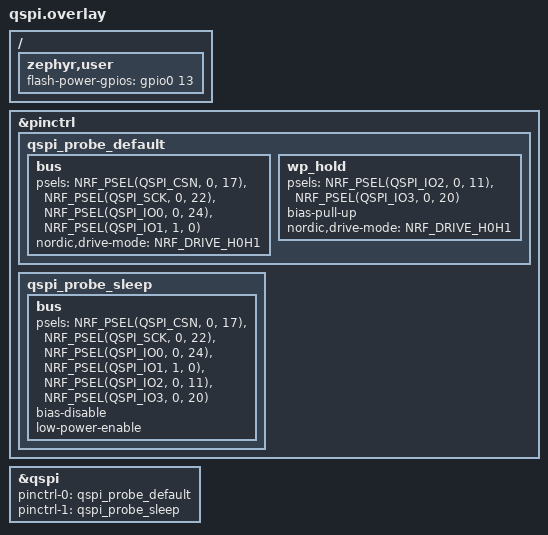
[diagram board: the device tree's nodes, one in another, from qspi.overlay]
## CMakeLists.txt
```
cmake_minimum_required(VERSION 3.20.0)
option(JAVELIN_PROBE "Run the native Javelin dictionary reader from external flash" OFF)
if(JAVELIN_PROBE)
  list(APPEND EXTRA_CONF_FILE "${CMAKE_CURRENT_SOURCE_DIR}/javelin.conf")
endif()
find_package(Zephyr REQUIRED HINTS $ENV{ZEPHYR_BASE})
project(steno_squid_qspi_probe)
target_sources(app PRIVATE src/main.c)

option(QUAD_PROBE "Build the separate quad-read diagnostic image" OFF)
option(SCRATCH_PROBE "Build the scratch-sector program and erase diagnostic image" OFF)
option(TRACE_PROBE "Repeat quad reads for waveform capture and timing comparison" OFF)
option(XIP_PROBE "Compare mapped quad reads with EasyDMA" OFF)
if(TRACE_PROBE AND NOT SCRATCH_PROBE)
  message(FATAL_ERROR "TRACE_PROBE requires SCRATCH_PROBE")
endif()
if(XIP_PROBE AND (NOT SCRATCH_PROBE OR TRACE_PROBE))
  message(FATAL_ERROR "XIP_PROBE requires SCRATCH_PROBE and a separate build from TRACE_PROBE")
endif()
if(JAVELIN_PROBE AND (NOT SCRATCH_PROBE OR XIP_PROBE OR TRACE_PROBE))
  message(FATAL_ERROR "JAVELIN_PROBE requires SCRATCH_PROBE and its own build directory")
endif()
if(QUAD_PROBE OR SCRATCH_PROBE)
  target_sources(app PRIVATE src/quad.c)
  target_compile_definitions(app PRIVATE QUAD_PROBE=1)
endif()
if(SCRATCH_PROBE)
  target_sources(app PRIVATE src/scratch.c)
  target_compile_definitions(app PRIVATE SCRATCH_PROBE=1)
endif()
if(TRACE_PROBE)
  target_sources(app PRIVATE src/trace.c)
  target_compile_definitions(app PRIVATE TRACE_PROBE=1)
endif()
if(XIP_PROBE OR JAVELIN_PROBE)
  target_sources(app PRIVATE src/mapped.c)
endif()
if(XIP_PROBE)
  target_compile_definitions(app PRIVATE XIP_PROBE=1)
endif()
if(JAVELIN_PROBE)
  include(javelin.cmake)
endif()
```

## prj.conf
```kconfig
CONFIG_GPIO=y
CONFIG_PINCTRL=y
CONFIG_NRFX_QSPI=y

CONFIG_BUILD_OUTPUT_UF2=y
CONFIG_BUILD_OUTPUT_UF2_FAMILY_ID="0xada52840"
CONFIG_USE_DT_CODE_PARTITION=y

CONFIG_USB_DEVICE_STACK=y
CONFIG_USB_DEVICE_INITIALIZE_AT_BOOT=n
CONFIG_USB_DEVICE_PRODUCT="Steno Squid QSPI Probe"
CONFIG_SERIAL=y
CONFIG_CONSOLE=y
CONFIG_UART_CONSOLE=y
CONFIG_UART_LINE_CTRL=y

CONFIG_LOG=y
CONFIG_LOG_MODE_IMMEDIATE=y
CONFIG_LOG_PRINTK=n
CONFIG_USE_SEGGER_RTT=y
CONFIG_LOG_BACKEND_RTT=y
CONFIG_LOG_BACKEND_UART=n
```

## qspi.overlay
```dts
#include <zephyr/dt-bindings/gpio/gpio.h>
#include <zephyr/dt-bindings/pinctrl/nrf-pinctrl.h>

/ {
	zephyr,user {
		flash-power-gpios = <&gpio0 13 GPIO_ACTIVE_HIGH>;
	};
};

&pinctrl {
	qspi_probe_default: qspi_probe_default {
		bus {
			psels = <NRF_PSEL(QSPI_CSN, 0, 17)>,
				<NRF_PSEL(QSPI_SCK, 0, 22)>,
				<NRF_PSEL(QSPI_IO0, 0, 24)>,
				<NRF_PSEL(QSPI_IO1, 1, 0)>;
			nordic,drive-mode = <NRF_DRIVE_H0H1>;
		};
		wp_hold {
			psels = <NRF_PSEL(QSPI_IO2, 0, 11)>,
				<NRF_PSEL(QSPI_IO3, 0, 20)>;
			bias-pull-up;
			nordic,drive-mode = <NRF_DRIVE_H0H1>;
		};
	};

	qspi_probe_sleep: qspi_probe_sleep {
		bus {
			psels = <NRF_PSEL(QSPI_CSN, 0, 17)>,
				<NRF_PSEL(QSPI_SCK, 0, 22)>,
				<NRF_PSEL(QSPI_IO0, 0, 24)>,
				<NRF_PSEL(QSPI_IO1, 1, 0)>,
				<NRF_PSEL(QSPI_IO2, 0, 11)>,
				<NRF_PSEL(QSPI_IO3, 0, 20)>;
			bias-disable;
			low-power-enable;
		};
	};
};

&qspi {
	status = "okay";
	pinctrl-0 = <&qspi_probe_default>;
	pinctrl-1 = <&qspi_probe_sleep>;
	pinctrl-names = "default", "sleep";
};
```

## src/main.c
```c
#include <nrfx_qspi.h>

#ifdef QUAD_PROBE
#include "quad.h"
#endif
#ifdef SCRATCH_PROBE
#include "scratch.h"
#endif

#include <zephyr/device.h>
#include <zephyr/devicetree.h>
#include <zephyr/drivers/gpio.h>
#include <zephyr/drivers/pinctrl.h>
#include <zephyr/drivers/uart.h>
#include <zephyr/kernel.h>
#include <zephyr/logging/log.h>
#include <zephyr/sys/printk.h>
#include <zephyr/usb/usb_device.h>

LOG_MODULE_REGISTER(qspi_probe);

#define QSPI_NODE DT_NODELABEL(qspi)

PINCTRL_DT_DEFINE(QSPI_NODE);

static const struct gpio_dt_spec flash_power =
	GPIO_DT_SPEC_GET(DT_PATH(zephyr_user), flash_power_gpios);
static const struct gpio_dt_spec status_led =
	GPIO_DT_SPEC_GET(DT_NODELABEL(blue_led), gpios);
static const struct device *const console = DEVICE_DT_GET(DT_CHOSEN(zephyr_console));

static const nrf_qspi_cinstr_conf_t read_id = {
	.opcode = 0x9f,
	.length = NRF_QSPI_CINSTR_LEN_4B,
	.io2_level = true,
	.io3_level = true,
	.wipwait = false,
	.wren = false,
};

struct probe_result {
	const char *failure;
	int gpio_or_pinctrl_error;
	nrfx_err_t nrfx_error;
	bool id_read;
	uint8_t id[3];
	uint8_t data[16] __aligned(4);
#ifdef QUAD_PROBE
	struct quad_result quad;
#endif
#ifdef SCRATCH_PROBE
	struct scratch_result scratch;
#endif
};

static void run_probe(struct probe_result *result)
{
	nrfx_qspi_config_t config = NRFX_QSPI_DEFAULT_CONFIG(
		NRF_QSPI_PIN_NOT_CONNECTED, NRF_QSPI_PIN_NOT_CONNECTED,
		NRF_QSPI_PIN_NOT_CONNECTED, NRF_QSPI_PIN_NOT_CONNECTED,
		NRF_QSPI_PIN_NOT_CONNECTED, NRF_QSPI_PIN_NOT_CONNECTED);

	/* Zephyr pinctrl supplies both the pin assignments and GPIO configuration. */
	config.skip_gpio_cfg = true;
	config.skip_psel_cfg = true;
	config.phy_if.sck_freq = NRF_QSPI_FREQ_DIV16;

	printk("Enabling switched flash VCC\n");
	if (!gpio_is_ready_dt(&flash_power)) {
		result->failure = "VCC GPIO device unavailable";
		return;
	}
	result->gpio_or_pinctrl_error = gpio_pin_configure_dt(&flash_power, GPIO_OUTPUT_ACTIVE);
	if (result->gpio_or_pinctrl_error) {
		result->failure = "VCC GPIO configuration";
		return;
	}
	k_msleep(50);

	printk("Applying QSPI pinctrl\n");
	result->gpio_or_pinctrl_error =
		pinctrl_apply_state(PINCTRL_DT_DEV_CONFIG_GET(QSPI_NODE), PINCTRL_STATE_DEFAULT);
	if (result->gpio_or_pinctrl_error) {
		result->failure = "QSPI pinctrl";
		return;
	}

	printk("Initializing Nordic QSPI (2 MHz, FASTREAD, 24-bit address)\n");
	result->nrfx_error = nrfx_qspi_init(&config, NULL, NULL);
	if (result->nrfx_error != NRFX_SUCCESS) {
		result->failure = "nrfx_qspi_init";
		return;
	}

	printk("Activating QSPI\n");
	result->nrfx_error = nrfx_qspi_activate(true);
	if (result->nrfx_error != NRFX_SUCCESS) {
		result->failure = "nrfx_qspi_activate";
		return;
	}

	printk("Reading JEDEC ID (0x9F)\n");
	result->nrfx_error = nrfx_qspi_cinstr_xfer(&read_id, NULL, result->id);
	if (result->nrfx_error != NRFX_SUCCESS) {
		result->failure = "JEDEC ID transfer";
		return;
	}
	result->id_read = true;

	if (result->id[0] != 0xef || result->id[1] != 0x40 || result->id[2] != 0x18) {
		result->failure = "unexpected JEDEC ID";
		return;
	}

	printk("Reading 16 bytes at 0x000000 with FASTREAD (0x0B)\n");
	result->nrfx_error = nrfx_qspi_read(result->data, sizeof(result->data), 0);
	if (result->nrfx_error != NRFX_SUCCESS) {
		result->failure = "FASTREAD transfer";
		return;
	}
#ifdef SCRATCH_PROBE
	run_scratch_probe(&config, &result->scratch, &result->quad);
#elif defined(QUAD_PROBE)
	run_quad_probe(&config, &result->quad, 0, 64 * 1024);
#endif
}

static void print_result(const struct probe_result *result)
{
	if (result->id_read) {
		printk("JEDEC ID: %02X %02X %02X (expected EF 40 18)\n",
		       result->id[0], result->id[1], result->id[2]);
	}
	if (result->failure) {
		printk("FAIL: %s; Zephyr rc=%d, nrfx rc=0x%08x\n",
		       result->failure, result->gpio_or_pinctrl_error, (unsigned int)result->nrfx_error);
		return;
	}

	printk("FASTREAD 0x000000:");
	for (size_t i = 0; i < sizeof(result->data); i++) {
		printk(" %02X", result->data[i]);
	}
#ifdef SCRATCH_PROBE
	printk("\nScratch %s (nrfx rc=0x%08x)\n",
	       result->scratch.outcome, (unsigned int)result->scratch.error);
	if (result->scratch.cleanup) {
		printk("Scratch cleanup %s (nrfx rc=0x%08x)\n",
		       result->scratch.cleanup, (unsigned int)result->scratch.cleanup_error);
	}
#endif
#ifdef QUAD_PROBE
	if (result->quad.outcome) {
		printk("\nQuad %s (compared %u bytes, lane mask 0x%x, nrfx rc=0x%08x)\n",
		       result->quad.outcome, result->quad.compared_bytes, result->quad.lane_coverage,
		       (unsigned int)result->quad.error);
#ifdef XIP_PROBE
		if (result->quad.mapped.outcome) {
			printk("XIP %s (matched %u words, nrfx rc=0x%08x)\n",
			       result->quad.mapped.outcome, result->quad.mapped.matched_words,
			       (unsigned int)result->quad.mapped.dma_error);
		}
#endif
#ifdef JAVELIN_PROBE
		if (result->quad.javelin_outcome) {
			printk("Javelin %s\n", result->quad.javelin_outcome);
			if (result->quad.phrase[0]) {
				printk("Javelin phrase: %s\n", result->quad.phrase);
			}
		}
#endif
		if (result->quad.restore_error != NRFX_SUCCESS) {
			printk("Quad SR2 restore failed: nrfx rc=0x%08x; power-cycle the flash\n",
			       (unsigned int)result->quad.restore_error);
		}
	}
#else
	printk("\nPASS: JEDEC ID and 16-byte single-data-line read completed\n");
#endif
}

int main(void)
{
	struct probe_result result = {.nrfx_error = NRFX_SUCCESS};
	uint32_t dtr = 0;
	bool led_ready = gpio_is_ready_dt(&status_led) &&
			 gpio_pin_configure_dt(&status_led, GPIO_OUTPUT_ACTIVE) == 0;
	int rc = device_is_ready(console) ? usb_enable(NULL) : -ENODEV;

	if (rc) {
		LOG_ERR("USB CDC startup failed: %d", rc);
		for (;;) {
			if (led_ready) {
				gpio_pin_toggle_dt(&status_led);
			}
			k_msleep(120);
		}
	}

	while (!dtr) {
		rc = uart_line_ctrl_get(console, UART_LINE_CTRL_DTR, &dtr);
		if (rc) {
			LOG_ERR("CDC DTR query failed: %d", rc);
		}
		k_msleep(100);
	}
	if (led_ready) {
		gpio_pin_set_dt(&status_led, 0);
	}

#ifdef TRACE_PROBE
	printk("\nSteno Squid QSPI trace ready. Arm the analyzer, then send t.\n");
	for (;;) {
		unsigned char key;

		if (uart_poll_in(console, &key) == 0 && key == 't') {
			break;
		}
		k_msleep(20);
	}
#elif defined(XIP_PROBE)
	printk("\nSteno Squid QSPI probe - mapped quad data reads\n");
#elif defined(JAVELIN_PROBE)
	printk("\nSteno Squid QSPI probe - native Javelin mapped dictionary\n");
#elif defined(SCRATCH_PROBE)
	printk("\nSteno Squid QSPI probe - scratch-sector program, read and erase\n");
#elif defined(QUAD_PROBE)
	printk("\n%s - quad output with volatile QE if needed\n", CONFIG_USB_DEVICE_PRODUCT);
#else
	printk("\n%s - read only\n", CONFIG_USB_DEVICE_PRODUCT);
#endif
	run_probe(&result);
	for (;;) {
		print_result(&result);
		k_sleep(K_SECONDS(3));
	}
}
```

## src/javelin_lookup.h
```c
#ifndef STENO_SQUID_JAVELIN_LOOKUP_H
#define STENO_SQUID_JAVELIN_LOOKUP_H

#include <stdint.h>

#ifdef __cplusplus
extern "C" {
#endif

extern const uint8_t javelin_fixture_start[];
extern const uint8_t javelin_fixture_end[];

const char *javelin_lookup_phrase(uintptr_t address, char *phrase);
#define JAVELIN_PHRASE_SIZE 32

#ifdef __cplusplus
}
#endif

#endif
```

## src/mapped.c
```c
#include "mapped.h"
#include "scratch.h"

#include <zephyr/devicetree.h>
#include <zephyr/kernel.h>
#include <zephyr/sys/printk.h>

#define XIP_BASE DT_REG_ADDR_BY_NAME(DT_NODELABEL(qspi), qspi_mm)
#define PAGE_WORDS (QUAD_SAMPLE_SIZE / sizeof(uint32_t))

static uint32_t dma_page[2][PAGE_WORDS];

void run_mapped_probe(struct mapped_result *result, uint32_t first_address)
{
	const uint32_t addresses[] = {first_address, result->second_address};
	const uint8_t patterns[] = {SCRATCH_FIRST_PATTERN, SCRATCH_SECOND_PATTERN};
	uintptr_t mismatch_address = 0;
	uint32_t mismatch_expected = 0;
	uint32_t mismatch_actual = 0;

	for (size_t page = 0; page < ARRAY_SIZE(addresses); page++) {
		result->dma_error = nrfx_qspi_read(dma_page[page], sizeof(dma_page[page]),
						 addresses[page]);
		if (result->dma_error != NRFX_SUCCESS) {
			result->outcome = "FAIL: quad EasyDMA reference read";
			return;
		}
		const uint8_t *reference = (const uint8_t *)dma_page[page];

		for (size_t byte = 0; byte < sizeof(dma_page[page]); byte++) {
			if (reference[byte] != ((uint8_t)byte ^ patterns[page])) {
				printk("Quad EasyDMA pattern mismatch at 0x%06x\n",
				       addresses[page] + (unsigned int)byte);
				result->outcome = "FAIL: quad EasyDMA reference differs from programmed pattern";
				return;
			}
		}
	}

	printk("Reading mapped quad pages at 0x%08x and 0x%08x\n",
	       (unsigned int)(XIP_BASE + addresses[0]), (unsigned int)(XIP_BASE + addresses[1]));
	for (size_t page = 0; page < ARRAY_SIZE(addresses); page++) {
		const volatile uint32_t *mapped =
			(const volatile uint32_t *)(XIP_BASE + addresses[page]);

		for (size_t word = 0; word < PAGE_WORDS; word++) {
			uint32_t actual = mapped[word];
			uint32_t expected = dma_page[page][word];

			if (actual == expected) {
				result->matched_words++;
			} else if (mismatch_address == 0) {
				mismatch_address = (uintptr_t)&mapped[word];
				mismatch_expected = expected;
				mismatch_actual = actual;
			}
		}
	}

	if (!reactivate_after_xip()) {
		result->reactivation_failed = true;
		result->outcome = "FAIL: QSPI did not become ready after mapped reads";
		return;
	}
	if (mismatch_address) {
		printk("Mapped mismatch at 0x%08x: expected %08x, got %08x\n",
		       (unsigned int)mismatch_address, mismatch_expected, mismatch_actual);
		result->outcome = "FAIL: mapped reads differ from quad EasyDMA";
		return;
	}
	result->outcome = "PASS: both mapped pages match quad EasyDMA";
}
```

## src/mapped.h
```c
#ifndef STENO_SQUID_MAPPED_H
#define STENO_SQUID_MAPPED_H

#include <nrfx_qspi.h>

struct mapped_result {
	const char *outcome;
	uint32_t second_address;
	unsigned int matched_words;
	nrfx_err_t dma_error;
	bool reactivation_failed;
};

void run_mapped_probe(struct mapped_result *result, uint32_t first_address);

#endif
```

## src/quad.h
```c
#ifndef STENO_SQUID_QUAD_H
#define STENO_SQUID_QUAD_H

#include <nrfx_qspi.h>
#ifdef XIP_PROBE
#include "mapped.h"
#endif
#ifdef JAVELIN_PROBE
#include "javelin_lookup.h"
#endif

struct quad_result {
	const char *outcome;
	nrfx_err_t error;
	nrfx_err_t restore_error;
	uint32_t compared_bytes;
	uint8_t lane_coverage;
#ifdef XIP_PROBE
	struct mapped_result mapped;
#endif
#ifdef JAVELIN_PROBE
	const char *javelin_outcome;
	char phrase[JAVELIN_PHRASE_SIZE];
	bool javelin_reactivation_failed;
#endif
};

#define QUAD_SAMPLE_SIZE 256

nrfx_err_t w25q128_enable_volatile_quad(void);
bool reactivate_after_xip(void);

void run_quad_probe(nrfx_qspi_config_t *config, struct quad_result *result,
		    uint32_t start, uint32_t length);

#endif
```

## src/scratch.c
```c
#include "scratch.h"

#include <string.h>
#include <zephyr/kernel.h>
#include <zephyr/sys/printk.h>

#define FLASH_BYTES (16U * 1024U * 1024U)
#define SECTOR_BYTES 4096U
#define SCRATCH_ADDRESS (FLASH_BYTES - SECTOR_BYTES)
#define PAGE_BYTES QUAD_SAMPLE_SIZE

static uint8_t page[PAGE_BYTES] __aligned(4);
static uint8_t readback[PAGE_BYTES] __aligned(4);

static nrfx_err_t wait_until_ready(void)
{
	int64_t deadline = k_uptime_get() + 2000;

	do {
		nrfx_err_t rc = nrfx_qspi_mem_busy_check();

		if (rc != NRFX_ERROR_BUSY) {
			return rc;
		}
		k_msleep(2);
	} while (k_uptime_get() < deadline);

	return NRFX_ERROR_TIMEOUT;
}

static nrfx_err_t verify_erased(bool *blank)
{
	*blank = false;
	for (uint32_t offset = 0; offset < SECTOR_BYTES; offset += sizeof(readback)) {
		nrfx_err_t rc = nrfx_qspi_read(readback, sizeof(readback), SCRATCH_ADDRESS + offset);

		if (rc != NRFX_SUCCESS) {
			return rc;
		}
		for (size_t i = 0; i < sizeof(readback); i++) {
			if (readback[i] != 0xff) {
				return NRFX_SUCCESS;
			}
		}
	}
	*blank = true;
	return NRFX_SUCCESS;
}

#ifndef JAVELIN_PROBE
static void fill_pattern(uint8_t pattern)
{
	for (size_t i = 0; i < sizeof(page); i++) {
		page[i] = (uint8_t)i ^ pattern;
	}
}
#endif

static const char *program_and_read(uint32_t address, nrfx_err_t *rc)
{
	printk("Programming %u bytes at 0x%06x (single-data-line Page Program)\n",
	       (unsigned int)sizeof(page), address);
	*rc = nrfx_qspi_write(page, sizeof(page), address);
	if (*rc != NRFX_SUCCESS) {
		return "FAIL: page program command";
	}
	*rc = wait_until_ready();
	if (*rc != NRFX_SUCCESS) {
		return "FAIL: waiting for page program";
	}
	*rc = nrfx_qspi_read(readback, sizeof(readback), address);
	if (*rc != NRFX_SUCCESS) {
		return "FAIL: programmed page read";
	}
	if (memcmp(page, readback, sizeof(page)) != 0) {
		for (size_t i = 0; i < sizeof(page); i++) {
			if (page[i] != readback[i]) {
				printk("Mismatch at 0x%06x: expected %02X, got %02X\n",
				       address + (unsigned int)i, page[i], readback[i]);
				break;
			}
		}
		return "FAIL: programmed page differs from expected pattern";
	}
	return NULL;
}

static const char *erase_and_verify(nrfx_qspi_config_t *config, nrfx_err_t *rc)
{
	bool blank;

	config->prot_if.readoc = NRF_QSPI_READOC_FASTREAD;
	*rc = nrfx_qspi_reconfigure(config);
	if (*rc != NRFX_SUCCESS) {
		return "FAIL: reconfiguring single-data-line reads";
	}
	*rc = wait_until_ready();
	if (*rc != NRFX_SUCCESS) {
		return "FAIL: waiting before sector erase";
	}
	printk("Erasing the 4 KiB scratch sector at 0x%06x\n", SCRATCH_ADDRESS);
	*rc = nrfx_qspi_erase(NRF_QSPI_ERASE_LEN_4KB, SCRATCH_ADDRESS);
	if (*rc != NRFX_SUCCESS) {
		return "FAIL: sector erase command";
	}
	*rc = wait_until_ready();
	if (*rc != NRFX_SUCCESS) {
		return "FAIL: waiting for sector erase";
	}
	*rc = verify_erased(&blank);
	if (*rc != NRFX_SUCCESS) {
		return "FAIL: reading sector after erase";
	}
	return blank ? "PASS: all 4,096 bytes verified as FF" : "FAIL: sector still contains data";
}

void run_scratch_probe(nrfx_qspi_config_t *config, struct scratch_result *result,
		       struct quad_result *quad)
{
	bool blank;

	printk("Checking all 4 KiB at 0x%06x before writing\n", SCRATCH_ADDRESS);
	result->error = verify_erased(&blank);
	if (result->error != NRFX_SUCCESS) {
		result->outcome = "FAIL: initial scratch-sector read";
		return;
	}
	if (!blank) {
		result->outcome = "SKIP: scratch sector contains data";
		return;
	}

#ifdef JAVELIN_PROBE
	const size_t fixture_size = javelin_fixture_end - javelin_fixture_start;
	if (fixture_size == 0 || fixture_size > sizeof(page)) {
		result->outcome = "FAIL: Javelin fixture does not fit scratch page";
		return;
	}
	memset(page, 0xff, sizeof(page));
	memcpy(page, javelin_fixture_start, fixture_size);
	printk("Staging %u-byte JSC4 fixture in the external scratch sector\n",
	       (unsigned int)fixture_size);
#else
	fill_pattern(SCRATCH_FIRST_PATTERN);
#endif
	result->outcome = program_and_read(SCRATCH_ADDRESS, &result->error);
#ifdef XIP_PROBE
	quad->mapped.second_address = SCRATCH_ADDRESS + SECTOR_BYTES - PAGE_BYTES;
	if (!result->outcome) {
		fill_pattern(SCRATCH_SECOND_PATTERN);
		result->outcome = program_and_read(quad->mapped.second_address, &result->error);
	}
#endif
	if (!result->outcome) {
#ifdef XIP_PROBE
		result->outcome = "PASS: both 256-byte programmed pages matched";
#else
		result->outcome = "PASS: all 256 programmed bytes matched";
#endif
		run_quad_probe(config, quad, SCRATCH_ADDRESS, sizeof(page));
	}
#ifdef XIP_PROBE
	if (quad->mapped.reactivation_failed) {
#elif defined(JAVELIN_PROBE)
	if (quad->javelin_reactivation_failed) {
#endif
#if defined(XIP_PROBE) || defined(JAVELIN_PROBE)
		result->cleanup = "SKIP: QSPI reactivation failed; scratch data may remain";
		result->cleanup_error = NRFX_ERROR_TIMEOUT;
		return;
	}
#endif
	result->cleanup = erase_and_verify(config, &result->cleanup_error);
}
```

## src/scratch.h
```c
#ifndef STENO_SQUID_SCRATCH_H
#define STENO_SQUID_SCRATCH_H

#include "quad.h"

#define SCRATCH_FIRST_PATTERN 0xa5
#define SCRATCH_SECOND_PATTERN 0x3c

struct scratch_result {
	const char *outcome;
	const char *cleanup;
	nrfx_err_t error;
	nrfx_err_t cleanup_error;
};

void run_scratch_probe(nrfx_qspi_config_t *config, struct scratch_result *result,
		       struct quad_result *quad);

#endif
```

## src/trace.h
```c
#ifndef STENO_SQUID_TRACE_H
#define STENO_SQUID_TRACE_H

#include <stdint.h>

void run_quad_trace(uint32_t address, const uint8_t *expected);

#endif
```

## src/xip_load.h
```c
#ifndef STENO_SQUID_XIP_LOAD_H
#define STENO_SQUID_XIP_LOAD_H

#include <stddef.h>
#include <stdint.h>

// Keep subword reads out of the memory window (erratum 118), and serialize
// each load before using its value in a dependent access (erratum 216).
static inline uint32_t xip_load_word(const void *address)
{
	const auto value = *static_cast<const volatile uint32_t *>(address);
	asm volatile("dsb" ::: "memory");
	return value;
}

static inline uint8_t xip_load_byte(const void *address)
{
	const auto offset = reinterpret_cast<uintptr_t>(address);
	const auto word = xip_load_word(reinterpret_cast<const void *>(offset & ~uintptr_t(3)));
	return static_cast<uint8_t>(word >> (8 * (offset & 3)));
}

static inline uint32_t xip_load_u24(const void *address)
{
	const auto *bytes = static_cast<const uint8_t *>(address);
	const uint32_t low = xip_load_byte(bytes);
	const uint32_t middle = xip_load_byte(bytes + 1);
	const uint32_t high = xip_load_byte(bytes + 2);
	return low | (middle << 8) | (high << 16);
}

static inline void copy_xip_bytes(void *destination, const void *address, size_t length)
{
	auto *out = static_cast<uint8_t *>(destination);
	const auto *in = static_cast<const uint8_t *>(address);
	for (size_t i = 0; i < length; ++i) {
		out[i] = xip_load_byte(in + i);
	}
}

#endif
```
